# S6E2D3xG register map
Vendor: Cypress; File version: 2.1
CPU: CM4 r0p1, little endian, MPU, FPU, 4 interrupt priority bits
Registers are 32-bit, read-write, reset 0x0 unless marked. A register's access mark holds for its fields unless they carry their own. Offsets are from the block's base; [hi:lo] are bit positions.

## GDCSUB — GDC Subsystem control registers
Base 0xD0A00000
0x00 LOCKUNLOCK wo — Lock Protection Setting register [W]
  [31:0] LOCKUNLOCK — Protection key of this address block setting bits
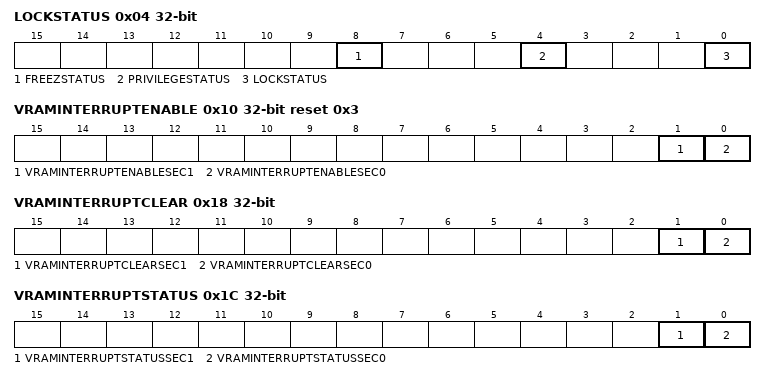
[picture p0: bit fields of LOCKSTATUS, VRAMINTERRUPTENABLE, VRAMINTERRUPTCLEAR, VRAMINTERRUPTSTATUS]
0x04 LOCKSTATUS ro — Lock Protection Status register [W]
  [8] FREEZSTATUS — Current status of freeze status
  [4] PRIVILEGESTATUS — Current status of privilege protection
  [0] LOCKSTATUS — Current status of lock protection
0x0C CONFIGCLOCKCONTROL reset 0x1 — CONFIG Clock control register [W]
  [2:0] CONFIGCLOCKSELECT — CONFIG Clock division ratio setting bits
0x10 VRAMINTERRUPTENABLE reset 0x3 — VRAM ECC error interrupt enable/disable register [W]
  [1] VRAMINTERRUPTENABLESEC1 — Interrupt control of VRAM ECC error for VRAM port1
  [0] VRAMINTERRUPTENABLESEC0 — Interrupt control of VRAM ECC error for VRAM port0
0x18 VRAMINTERRUPTCLEAR wo — VRAM ECC error interrupt clear register [W]
  [1] VRAMINTERRUPTCLEARSEC1 — Clear interrupt of VRAM ECC error for VRAM port1
  [0] VRAMINTERRUPTCLEARSEC0 — Clear interrupt of VRAM ECC error for VRAM port0
0x1C VRAMINTERRUPTSTATUS ro — VRAM ECC error interrupt status register [W]
  [1] VRAMINTERRUPTSTATUSSEC1 — Indicator of VRAM Interrupt status for VRAM port1
  [0] VRAMINTERRUPTSTATUSSEC0 — Indicator of VRAM Interrupt status for VRAM port0
0x20 EXTFLASHDEVSELECT reset 0x1 — External Flash Device Selection register [W]
  [0] EXTFLASHDEVSELECT — External memory device selection bit
0x24 VRAMREMAPDISABLE — VRAM Remap Mode Disable register [W]
  [0] VRAMREMAPDISABLE — VRAM address remap or non-remap selection bit
0x28 PANICSWITCH — Panic display mode switch register [W]
  [0] PANICSWITCH — Panic display mode or Normal display mode selection bit
0x2C GDC_CLOCKDIVIDER reset 0x40000 — GDC Clock Generation Control register [W]
  [23:8] GDCCLOCKSELECT — GDC clock generation control bits
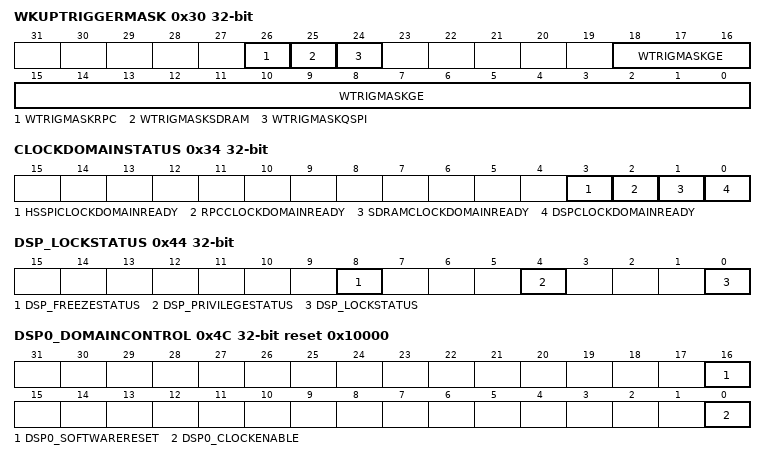
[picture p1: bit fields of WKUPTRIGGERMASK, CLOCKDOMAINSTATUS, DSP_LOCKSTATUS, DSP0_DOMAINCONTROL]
0x30 WKUPTRIGGERMASK — CPU wake-up trigger Mask register [W]
  [26] WTRIGMASKRPC — Wake up trigger mask for HyperBus interface
  [25] WTRIGMASKSDRAM — Wake up trigger mask for SDRAM interface
  [24] WTRIGMASKQSPI — Wake up trigger mask for QSPI interface
  [18:0] WTRIGMASKGE — Wake up trigger mask for GDC Core
0x34 CLOCKDOMAINSTATUS — Clock Domain Status Indication register [W]
  [3] HSSPICLOCKDOMAINREADY — Clock Status of QSPI interface clock domain
  [2] RPCCLOCKDOMAINREADY — Clock Status of HyperBus interface clock domain
  [1] SDRAMCLOCKDOMAINREADY — Clcok Status of SDRAM interface clock domain
  [0] DSPCLOCKDOMAINREADY — Clock Status of Display clock domain
0x40 DSP_LOCKUNLOCK wo — Display LockUnlock register [W]
  [31:0] DSP_LOCKUNLOCK — Protection key of this address block setting bits
0x44 DSP_LOCKSTATUS ro — Display Lock Status indication register [W]
  [8] DSP_FREEZESTATUS — Current status of freeze status
  [4] DSP_PRIVILEGESTATUS — Current status of provilege protection
  [0] DSP_LOCKSTATUS — Current status of lock protection
0x48 DSP0_CLOCKDIVIDER reset 0x41E000 — Display Clock Divider Ration Setting Register [W]
  [23:8] DSP0_CLOCKDIVIDER — Division ration from the Reference clock for peripherals
0x4C DSP0_DOMAINCONTROL reset 0x10000 — Display clock domain control register [W]
  [16] DSP0_SOFTWARERESET — Display clock domain software reset
  [0] DSP0_CLOCKENABLE — Display clock output control
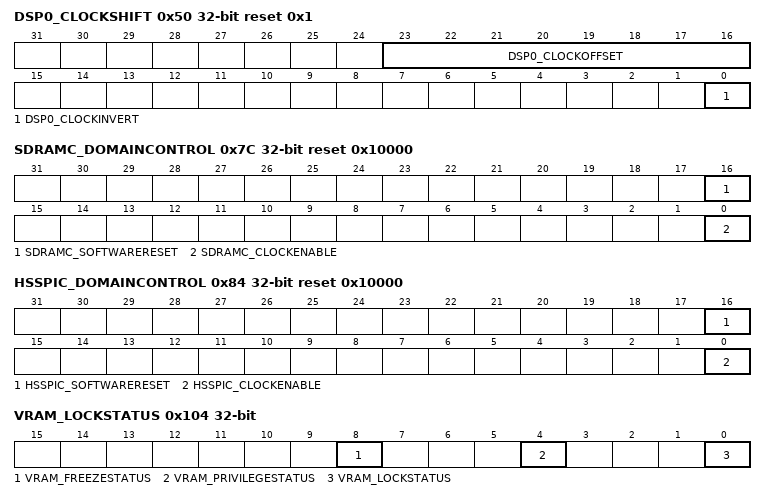
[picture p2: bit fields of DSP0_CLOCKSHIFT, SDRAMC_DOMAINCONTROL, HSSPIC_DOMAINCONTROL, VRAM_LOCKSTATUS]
0x50 DSP0_CLOCKSHIFT reset 0x1 — Register for display clock shift [W]
  [23:16] DSP0_CLOCKOFFSET — Display clock phase setting bits
  [0] DSP0_CLOCKINVERT — Display clock polarity setting bit
0x58 DSP0_POWERENCONTROL — Register for display Power Enable Signal Control [W]
  [0] POWER_ENABLE — Power control of external TFT panel setting bit
0x5C DSP0_CLOCKGATEMODELOCK wo — Display Clock Gate Mode Protection Control register [W]
  [31:0] LOCKUNLOCK — Protection of this address block setting bits
0x60 DSP0_CLOCKGATECONTROL — Display Clock Gate Control register [W]
  [0] CLOCKGATE_ENABLE — Dot clock for external TFT panel control bit
0x78 SDRAMC_CLOCKDIVIDER reset 0x40000 — Division Ratio of SDRAM interface setting register [W]
  [23:8] SDRAMC_CLOCKDIVIDER — Division ratio from the Reference clock for peripherals
0x7C SDRAMC_DOMAINCONTROL reset 0x10000 — SDRAM interface clock domain setting register [W]
  [16] SDRAMC_SOFTWARERESET — Software reset for SDRAM interface clock domain
  [0] SDRAMC_CLOCKENABLE — SDRAM interface clock output control
0x80 HSSPIC_CLOCKDIVIDER reset 0x40000 — Division Ratio of QSPI interface setting register [W]
  [23:8] HSSPIC_CLOCKDIVIDER — Division Ratio from the Reference clock for peripherals
0x84 HSSPIC_DOMAINCONTROL reset 0x10000 — QSPI interface clock domain setting register [W]
  [16] HSSPIC_SOFTWARERESET — Software reset for QSPI interface clock domain
  [0] HSSPIC_CLOCKENABLE — QSPI interface clock output control
0x88 RPCC_CLOCKDIVIDER — Division Ratio of HyperBus interface setting register [W]
  [2:0] RPCC_CLOCKDIVIDER — Division Ratio from the Reference clock for peripherals
0x8C RPCC_DOMAINCONTROL reset 0x10000 — HyperBus interface clock domain setting register [W]
  [0] RPCC_CLOCKENABLE — HyperBus interface clock output control
0x100 VRAM_LOCKUNLOCK wo — VRAM LockUnlock Register [W]
  [31:0] VRAM_LOCKUNLOCK — $
0x104 VRAM_LOCKSTATUS ro — Protection status Indication of this address block [W]
  [8] VRAM_FREEZESTATUS — Current status of freeze status
  [4] VRAM_PRIVILEGESTATUS — Current status of previlege protection
  [0] VRAM_LOCKSTATUS — Current status of lock protection
0x108 VRAM_SRAM_SELECT — Size of the ECC protected memory region selection register [W]
  [11:0] VRAM_SRAM_SELECT — Selects the size of the ECC protected region
0x13C VRAM_SBERRADDR_S0 ro — GDC bus address of the read access at S0 interface which had a single-bit ECC error [W]
  [31:0] VRAM_SBERRADDR_S0 — Indicates address which had an ECC single bit error
0x140 VRAM_SBERRADDR_S1 ro — GDC bus address of the read access at S1 interface which had a single-bit ECC error [W]
  [31:0] VRAM_SBERRADDR_S1 — Indicates address which had an ECC single bit error
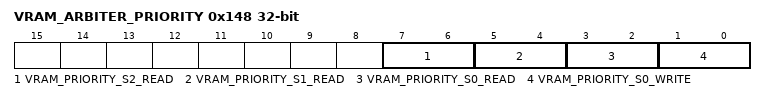
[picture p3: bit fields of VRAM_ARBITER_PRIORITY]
0x148 VRAM_ARBITER_PRIORITY — Register assigns fixed arbitration priorities to each GDC bus slave interface [W]
  [7:6] VRAM_PRIORITY_S2_READ — for internal device test purpose
  [5:4] VRAM_PRIORITY_S1_READ — set priority of S1 interface for read
  [3:2] VRAM_PRIORITY_S0_READ — set priority of S0 interface for read
  [1:0] VRAM_PRIORITY_S0_WRITE — set priority of S0 interface for write
